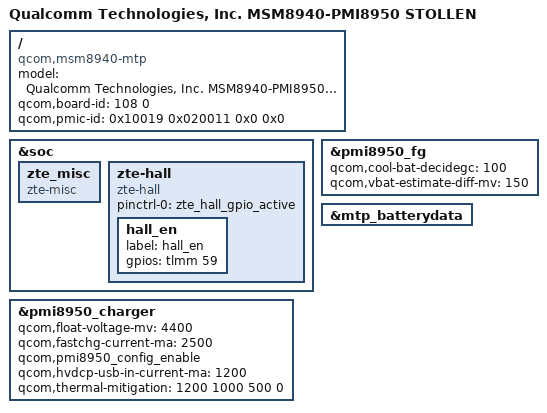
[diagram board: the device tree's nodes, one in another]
/*
 * Copyright (c) 2016, The Linux Foundation. All rights reserved.
 *
 * This program is free software; you can redistribute it and/or modify
 * it under the terms of the GNU General Public License version 2 and
 * only version 2 as published by the Free Software Foundation.
 *
 * This program is distributed in the hope that it will be useful,
 * but WITHOUT ANY WARRANTY; without even the implied warranty of
 * MERCHANTABILITY or FITNESS FOR A PARTICULAR PURPOSE.  See the
 * GNU General Public License for more details.
 */

/dts-v1/;

#include "msm8940.dtsi"
#include "msm8940-pmi8950-mtp.dtsi"
#include "zte-msm8940-stollen.dtsi"
#include "msm8940-camera-sensor-zte-stollen.dtsi"

#include "dsi-panel-truly-1080p-video.dtsi"
#include "dsi-panel-zte-tm-nt35695-tm-6p0-1080p-video.dtsi"
#include "dsi-panel-zte-lead_otm1906a_auo_6p0_1080p_cmd.dtsi"
#include "dsi-panel-zte-dijing-nt35695-auo-6p0-1080p-video.dtsi"

/ {
	model = "Qualcomm Technologies, Inc. MSM8940-PMI8950 STOLLEN";
	compatible = "qcom,msm8940-mtp", "qcom,msm8940", "qcom,mtp";
	qcom,board-id= <108 0>;
	qcom,pmic-id = <0x10019 0x020011 0x0 0x0>;
};

&soc {
	zte_misc {
		compatible = "zte-misc";
	};
	zte-hall {
		compatible = "zte-hall";
		pinctrl-names = "zte_hall_gpio_active";
		pinctrl-0 = <&zte_hall_gpio_active>;
		hall_en{
			label = "hall_en";
			gpios = <&tlmm 59 0x0>;
		};
	};
};

&pmi8950_charger {
	qcom,float-voltage-mv = <4400>;
	qcom,fastchg-current-ma = <2500>;
	qcom,pmi8950_config_enable;
	qcom,hvdcp-usb-in-current-ma = <1200>;
	qcom,thermal-mitigation = <1200 1000 500 0>;
};
&pmi8950_fg{
	qcom,cool-bat-decidegc = <100>;
	qcom,vbat-estimate-diff-mv = <150>;
};

&mtp_batterydata {
		#include "zte_p840a20_3400mah.dtsi"
};
